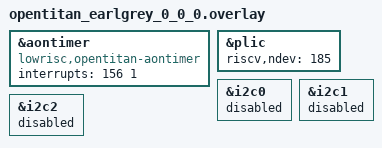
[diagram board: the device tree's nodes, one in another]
/*
 * Copyright The Zephyr Project Contributors
 *
 * SPDX-License-Identifier: Apache-2.0
 */

/* OpenTitan master @ 6a3c2e98, which has the same hardware as the Earlgrey-M2.5.x releases. */

&aontimer {
	compatible = "lowrisc,opentitan-aontimer";
	interrupts = <156 1>;
};

&plic {
	riscv,ndev = <185>;
};

/* The I2C driver supports only the I2C 2.0.0 IP, and this revision has I2C 1.0. */
&i2c0 {
	status = "disabled";
};

&i2c1 {
	status = "disabled";
};

&i2c2 {
	status = "disabled";
};
